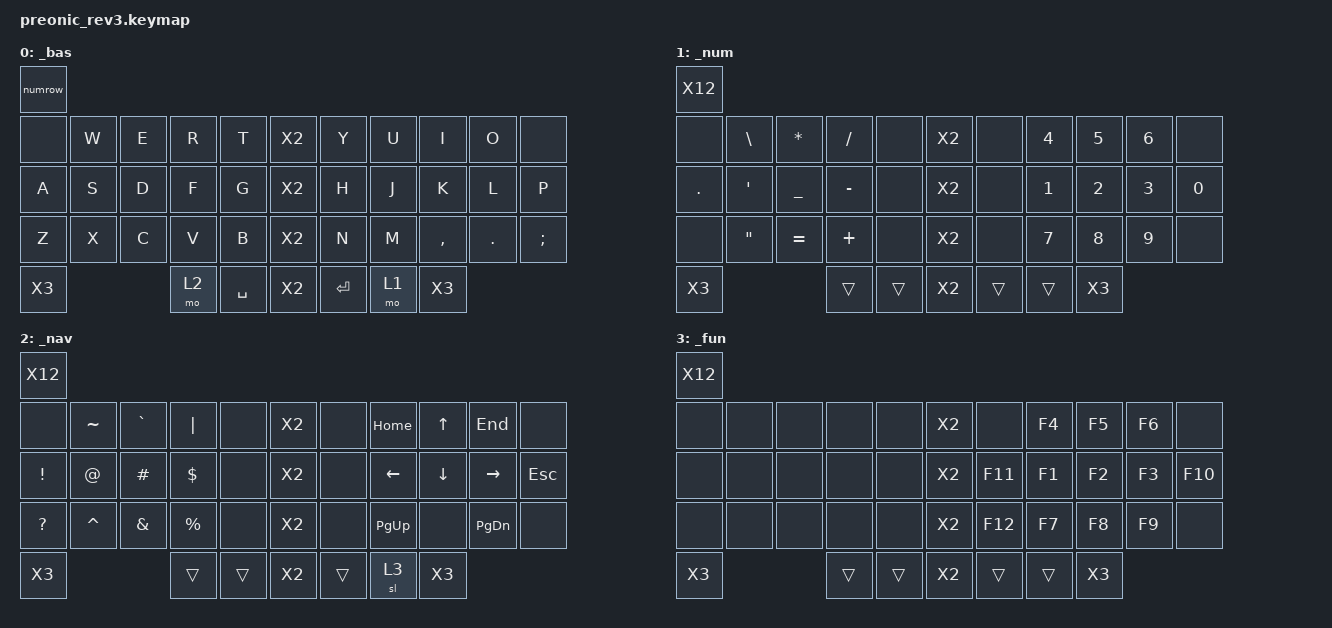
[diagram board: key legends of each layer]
#include <behaviors.dtsi>
#include <dt-bindings/zmk/keys.h>

#define X2 &none &none
#define X3 &none &none &none
#define X12 X3 X3 X3 X3
#define _numrow &kp N1 &kp N2 &kp N3 &kp N4 &kp N5 X2 &kp N6 &kp N7 &kp N8 &kp N9 &kp N0
/ {
    combos {
        compatible = "zmk,combos";

        cb_tab {
            bindings = <&kp TAB>;
            key-positions = <13 14>;
        };

        cb_del {
            bindings = <&kp DEL>;
            key-positions = <52 55>;
        };

        cb_cntl {
            bindings = <&sk LCTRL>;
            key-positions = <36 37>;
        };

        cb_shftl {
            bindings = <&sk LSHFT>;
            key-positions = <46 47>;
        };

        cb_shftr {
            bindings = <&sk LSHFT>;
            key-positions = <46 47>;
        };

        cb_gui {
            bindings = <&sk LGUI>;
            key-positions = <51 52>;
        };

        cb_alt {
            bindings = <&sk RALT>;
            key-positions = <55 56>;
        };

        cb_bkspc {
            bindings = <&kp BSPC>;
            key-positions = <21 22>;
        };

        cb_lbkt {
            bindings = <&kp LBKT>;
            layers = <0 1>;
            key-positions = <13 25>;
        };

        cb_lpara {
            bindings = <&kp LPAR>;
            layers = <0 1>;
            key-positions = <14 26>;
        };

        cb_lbrc {
            bindings = <&kp LBRC>;
            layers = <0 1>;
            key-positions = <15 27>;
        };

        cb_rbkt {
            bindings = <&kp RBRC>;
            layers = <0 1>;
            key-positions = <20 32>;
        };

        cb_rpara {
            bindings = <&kp RPAR>;
            layers = <0 1>;
            key-positions = <21 33>;
        };

        cb_rbrc {
            bindings = <&kp RBKT>;
            layers = <0 1>;
            key-positions = <22 34>;
        };

        cb_q {
            bindings = <&kp Q>;
            layers = <0>;
            key-positions = <13 24>;
        };

        cb_altf4 {
            bindings = <&kp LA(F4)>;
            key-positions = <17 18>;
        };
    };

    keymap {
        compatible = "zmk,keymap";

        _bas {
            bindings = <
  _numrow
  //────────────┬─────────────┬─────────────┬─────────────┬─────────────╮ ╭──╮ ╭─────────────┬─────────────┬─────────────┬─────────────┬─────────────╮
  &none         &kp W         &kp E        &kp R         &kp T             X2  &kp Y         &kp U         &kp I         &kp O         &none         
  &kp A         &kp S         &kp D        &kp F         &kp G             X2  &kp H         &kp J         &kp K         &kp L         &kp P         
  &kp Z         &kp X         &kp C        &kp V         &kp B             X2  &kp N         &kp M         &kp COMMA     &kp DOT       &kp SEMI  
  //────────────┴─────────────┴─────────────┼─────────────┼─────────────┤ ├──┤ ├─────────────┼─────────────┼─────────────┴─────────────┴─────────────╯    
  X3                                       &mo 2         &kp SPACE         X2  &kp ENTER     &mo 1         X3 
  //                                        ╰─────────────┴─────────────╯ ╰──╯ ╰─────────────┴─────────────╯
            >;
        };

        _num {
            bindings = <
  X12
  //────────────┬─────────────┬─────────────┬─────────────┬─────────────╮ ╭──╮ ╭─────────────┬─────────────┬─────────────┬─────────────┬─────────────╮        
  &none         &kp BSLH      &kp STAR     &kp FSLH      &none             X2  &none         &kp N4        &kp N5        &kp N6        &none             
  &kp DOT       &kp SQT       &kp UNDER    &kp MINUS     &none             X2  &none         &kp N1        &kp N2        &kp N3        &kp N0          
  &none         &kp DQT       &kp EQUAL    &kp PLUS      &none             X2  &none         &kp N7        &kp N8        &kp N9        &none    
  //────────────┴─────────────┴─────────────┼─────────────┼─────────────┤ ├──┤ ├─────────────┼─────────────┼─────────────┴─────────────┴─────────────╯          
  X3                                       &trans        &trans            X2  &trans        &trans        X3  
  //                                        ╰─────────────┴─────────────╯ ╰──╯ ╰─────────────┴─────────────╯ 
            >;
        };

        _nav {
            bindings = <
  X12
  //────────────┬─────────────┬─────────────┬─────────────┬─────────────╮ ╭──╮ ╭─────────────┬─────────────┬─────────────┬─────────────┬─────────────╮
  &none         &kp TILDE     &kp GRAVE    &kp PIPE      &none             X2  &none         &kp HOME      &kp UP        &kp END       &none        
  &kp EXCL      &kp AT        &kp POUND    &kp DLLR      &none             X2  &none         &kp LEFT      &kp DOWN      &kp RIGHT     &kp ESC      
  &kp QMARK     &kp CARET     &kp AMPS     &kp PRCNT     &none             X2  &none         &kp PG_UP     &none         &kp PG_DN     &none  
  //────────────┴─────────────┴─────────────┼─────────────┼─────────────┤ ├──┤ ├─────────────┼─────────────┼─────────────┴─────────────┴─────────────╯   
  X3                                       &trans        &trans            X2  &trans        &sl 3         X3   
  //                                        ╰─────────────┴─────────────╯ ╰──╯ ╰─────────────┴─────────────╯ 
            >;
        };

        _fun {
            bindings = <
  X12
  //────────────┬─────────────┬─────────────┬─────────────┬─────────────╮ ╭──╮ ╭─────────────┬─────────────┬─────────────┬─────────────┬─────────────╮
  &none         &none         &none        &none         &none             X2  &none         &kp F4        &kp F5        &kp F6        &none        
  &none         &none         &none        &none         &none             X2  &kp F11       &kp F1        &kp F2        &kp F3        &kp F10      
  &none         &none         &none        &none         &none             X2  &kp F12       &kp F7        &kp F8        &kp F9        &none   
  //────────────┴─────────────┴─────────────┼─────────────┼─────────────┤ ├──┤ ├─────────────┼─────────────┼─────────────┴─────────────┴─────────────╯      
  X3                                       &trans        &trans            X2  &trans        &trans        X3   
  //                                        ╰─────────────┴─────────────╯ ╰──╯ ╰─────────────┴─────────────╯      
            >;
        };
    };
};
